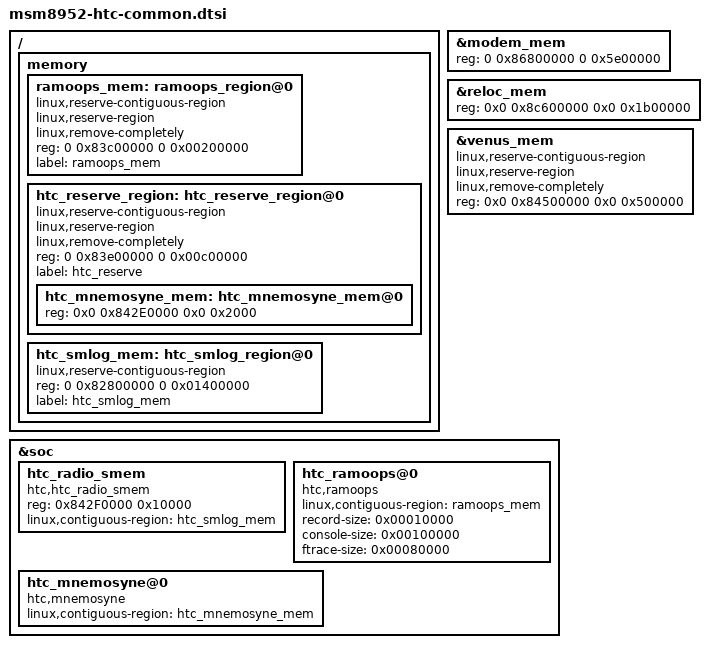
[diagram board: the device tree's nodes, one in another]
/*
 * msm8952-htc-common: common configs of HTC msm8952 projects
 */

&modem_mem {
	reg = <0 0x86800000 0 0x5e00000>;
};

&reloc_mem {
	reg = <0x0 0x8c600000 0x0 0x1b00000>;
};

&venus_mem {
	linux,reserve-contiguous-region;
	linux,reserve-region;
	linux,remove-completely;
	reg = <0x0 0x84500000 0x0 0x500000>;
};

/ {
	memory {
		ramoops_mem: ramoops_region@0 {
			linux,reserve-contiguous-region;
			linux,reserve-region;
			linux,remove-completely;
			reg = <0 0x83d00000 0 0x00100000>; /* 1 MB */
			label = "ramoops_mem";
		};

		ramoops_mem: ramoops_region@0 {
			linux,reserve-contiguous-region;
			linux,reserve-region;
			linux,remove-completely;
			reg = <0 0x83c00000 0 0x00200000>; /* 2 MB */
			label = "ramoops_mem";
		};

                htc_reserve_region: htc_reserve_region@0 {
                        linux,reserve-contiguous-region;
                        linux,reserve-region;
                        linux,remove-completely;
                        reg = <0 0x83e00000 0 0x00c00000>; /* 12 MB */
                        label = "htc_reserve";

			htc_mnemosyne_mem: htc_mnemosyne_mem@0 {
				reg = <0x0 0x842E0000 0x0 0x2000>; /* 8 KB */
			};
		 };


                htc_smlog_mem: htc_smlog_region@0 {
                        linux,reserve-contiguous-region;
                        reg = <0 0x82800000 0 0x01400000>; /* 20 MB */
                        label = "htc_smlog_mem";
                };
	};
};

&soc {
	htc_radio_smem {
		compatible = "htc,htc_radio_smem";
		reg = <0x842F0000 0x10000>;
		linux,contiguous-region = <&htc_smlog_mem>;
		reg-names = "smem-start-addr";
	};

	htc_ramoops@0 {
		compatible = "htc,ramoops";
		linux,contiguous-region = <&ramoops_mem>;
		record-size = <0x00010000>; /* 64 KB */
		console-size = <0x00100000>; /* 1024 KB  */
		ftrace-size = <0x00080000>; /* 512 KB */
	};

	htc_mnemosyne@0 {
		compatible = "htc,mnemosyne";
		linux,contiguous-region = <&htc_mnemosyne_mem>;
	};
};

